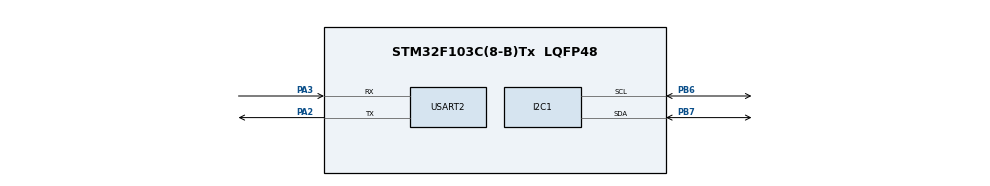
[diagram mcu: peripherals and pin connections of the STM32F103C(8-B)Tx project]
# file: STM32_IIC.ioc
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Mcu.Family=STM32F1
Mcu.Name=STM32F103C(8-B)Tx
Mcu.Package=LQFP48
NVIC.PriorityGroup=NVIC_PRIORITYGROUP_4
PA13.Mode=Serial_Wire
PA13.Signal=SYS_JTMS-SWDIO
PA14.Mode=Serial_Wire
PA14.Signal=SYS_JTCK-SWCLK
PA2.Mode=Asynchronous
PA2.Signal=USART2_TX
PA3.Mode=Asynchronous
PA3.Signal=USART2_RX
PB6.Mode=I2C
PB6.Signal=I2C1_SCL
PB7.Mode=I2C
PB7.Signal=I2C1_SDA
ProjectManager.HeapSize=0x200
ProjectManager.StackSize=0x400
ProjectManager.TargetToolchain=STM32CubeIDE
RCC.APB1Freq_Value=8000000
RCC.APB2Freq_Value=8000000
USART2.VirtualMode=VM_ASYNC
board=custom

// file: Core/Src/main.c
/* USER CODE BEGIN Header */
/**
 ******************************************************************************
 * @file           : main.c
 * @brief          : Main program body
 ******************************************************************************
 * @attention
 *
 * Copyright (c) 2022 STMicroelectronics.
 * All rights reserved.
 *
 * This software is licensed under terms that can be found in the LICENSE file
 * in the root directory of this software component.
 * If no LICENSE file comes with this software, it is provided AS-IS.
 *
 ******************************************************************************
 */
/* USER CODE END Header */
#include "main.h"
#include "gpio.h"
#include "i2c.h"
#include "usart.h"

/* USER CODE BEGIN Includes */
#include "aht20.h"
#include "stdio.h"
#include "string.h"
/* USER CODE END Includes */

void SystemClock_Config(void);

int main(void)
{

  /* MCU Configuration--------------------------------------------------------*/

  /* Reset of all peripherals, Initializes the Flash interface and the Systick. */
  HAL_Init();

  /* Configure the system clock */
  SystemClock_Config();

  /* Initialize all configured peripherals */
  MX_GPIO_Init();
  MX_I2C1_Init();
  MX_USART2_UART_Init();
  /* USER CODE BEGIN 2 */
  AHT20_Init();                // 初始化 AHT20
  float temperature, humidity; // 温度和湿度变量
  char message[50];            // 要发送的字符串

  /* USER CODE END 2 */

  /* Infinite loop */
  /* USER CODE BEGIN WHILE */

  while (1)
  {
    // 读取温湿度
    AHT20_Read(&temperature, &humidity);
    // 打印温湿度
    sprintf(message, "温度: %.1f ℃, 湿度: %.1f %%\r\n", temperature, humidity);
    // 串口发送

    HAL_UART_Transmit(&huart2, (uint8_t *)message, strlen(message), HAL_MAX_DELAY);
    // 延时 1 秒
    HAL_Delay(1000);

    /* USER CODE END WHILE */

  }
}

void SystemClock_Config(void)
{
  RCC_OscInitTypeDef RCC_OscInitStruct = {0};
  RCC_ClkInitTypeDef RCC_ClkInitStruct = {0};

  /** Initializes the RCC Oscillators according to the specified parameters
   * in the RCC_OscInitTypeDef structure.
   */
  RCC_OscInitStruct.OscillatorType = RCC_OSCILLATORTYPE_HSI;
  RCC_OscInitStruct.HSIState = RCC_HSI_ON;
  RCC_OscInitStruct.HSICalibrationValue = RCC_HSICALIBRATION_DEFAULT;
  RCC_OscInitStruct.PLL.PLLState = RCC_PLL_NONE;
  if (HAL_RCC_OscConfig(&RCC_OscInitStruct) != HAL_OK)
  {
    Error_Handler();
  }

  /** Initializes the CPU, AHB and APB buses clocks
   */
  RCC_ClkInitStruct.ClockType = RCC_CLOCKTYPE_HCLK | RCC_CLOCKTYPE_SYSCLK | RCC_CLOCKTYPE_PCLK1 | RCC_CLOCKTYPE_PCLK2;
  RCC_ClkInitStruct.SYSCLKSource = RCC_SYSCLKSOURCE_HSI;
  RCC_ClkInitStruct.AHBCLKDivider = RCC_SYSCLK_DIV1;
  RCC_ClkInitStruct.APB1CLKDivider = RCC_HCLK_DIV1;
  RCC_ClkInitStruct.APB2CLKDivider = RCC_HCLK_DIV1;

  if (HAL_RCC_ClockConfig(&RCC_ClkInitStruct, FLASH_LATENCY_0) != HAL_OK)
  {
    Error_Handler();
  }
}

void Error_Handler(void)
{
  __disable_irq();
  while (1)
  {
  }
}
